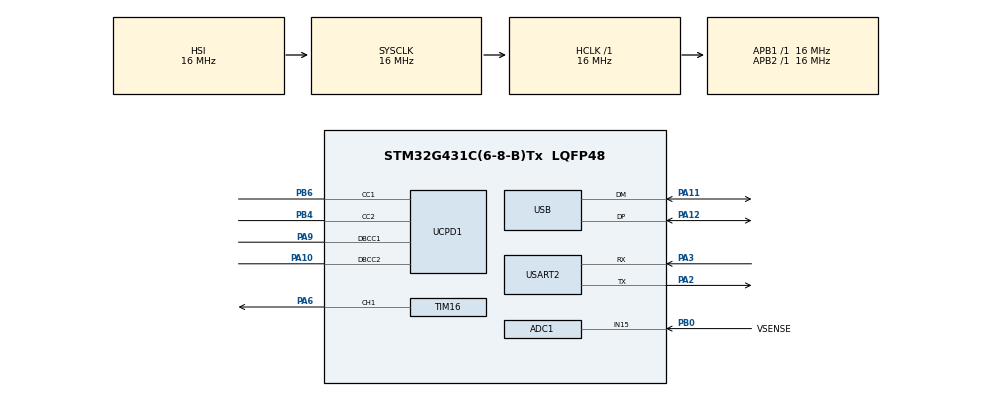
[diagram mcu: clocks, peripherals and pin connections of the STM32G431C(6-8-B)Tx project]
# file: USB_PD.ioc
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ADC1.Channel-0\#ChannelRegularConversion=ADC_CHANNEL_15
ADC1.ClockPrescaler=ADC_CLOCK_SYNC_PCLK_DIV4
ADC1.ContinuousConvMode=ENABLE
ADC1.NbrOfConversionFlag=1
ADC1.OffsetNumber-0\#ChannelRegularConversion=ADC_OFFSET_NONE
ADC1.Overrun=ADC_OVR_DATA_OVERWRITTEN
ADC1.Rank-0\#ChannelRegularConversion=1
ADC1.SamplingTime-0\#ChannelRegularConversion=ADC_SAMPLETIME_247CYCLES_5
ADC1.master=1
Dma.Request0=UCPD1_RX
Dma.Request1=UCPD1_TX
Dma.UCPD1_RX.0.Direction=DMA_PERIPH_TO_MEMORY
Dma.UCPD1_RX.0.EventEnable=DISABLE
Dma.UCPD1_RX.0.Instance=DMA1_Channel1
Dma.UCPD1_RX.0.MemDataAlignment=DMA_MDATAALIGN_BYTE
Dma.UCPD1_RX.0.MemInc=DMA_MINC_ENABLE
Dma.UCPD1_RX.0.Mode=DMA_NORMAL
Dma.UCPD1_RX.0.PeriphDataAlignment=DMA_PDATAALIGN_BYTE
Dma.UCPD1_RX.0.PeriphInc=DMA_PINC_DISABLE
Dma.UCPD1_RX.0.Polarity=HAL_DMAMUX_REQ_GEN_RISING
Dma.UCPD1_RX.0.Priority=DMA_PRIORITY_LOW
Dma.UCPD1_RX.0.RequestNumber=1
Dma.UCPD1_RX.0.SignalID=NONE
Dma.UCPD1_RX.0.SyncEnable=DISABLE
Dma.UCPD1_RX.0.SyncPolarity=HAL_DMAMUX_SYNC_NO_EVENT
Dma.UCPD1_RX.0.SyncRequestNumber=1
Dma.UCPD1_RX.0.SyncSignalID=NONE
Dma.UCPD1_TX.1.Direction=DMA_MEMORY_TO_PERIPH
Dma.UCPD1_TX.1.EventEnable=DISABLE
Dma.UCPD1_TX.1.Instance=DMA1_Channel2
Dma.UCPD1_TX.1.MemDataAlignment=DMA_MDATAALIGN_BYTE
Dma.UCPD1_TX.1.MemInc=DMA_MINC_ENABLE
Dma.UCPD1_TX.1.Mode=DMA_NORMAL
Dma.UCPD1_TX.1.PeriphDataAlignment=DMA_PDATAALIGN_BYTE
Dma.UCPD1_TX.1.PeriphInc=DMA_PINC_DISABLE
Dma.UCPD1_TX.1.Polarity=HAL_DMAMUX_REQ_GEN_RISING
Dma.UCPD1_TX.1.Priority=DMA_PRIORITY_LOW
Dma.UCPD1_TX.1.RequestNumber=1
Dma.UCPD1_TX.1.SignalID=NONE
Dma.UCPD1_TX.1.SyncEnable=DISABLE
Dma.UCPD1_TX.1.SyncPolarity=HAL_DMAMUX_SYNC_NO_EVENT
Dma.UCPD1_TX.1.SyncRequestNumber=1
Dma.UCPD1_TX.1.SyncSignalID=NONE
FREERTOS.INCLUDE_eTaskGetState=1
FREERTOS.Tasks01=defaultTask,24,128,StartDefaultTask,Default,NULL,Dynamic,NULL,NULL
FREERTOS.configTOTAL_HEAP_SIZE=7000
Mcu.Family=STM32G4
Mcu.Name=STM32G431C(6-8-B)Tx
Mcu.Package=LQFP48
Mcu.UserConstants=VDDA_APPLI,3300
NVIC.DMA1_Channel1_IRQn=true\:5\:0\:false\:false\:true\:true\:false\:true
NVIC.DMA1_Channel2_IRQn=true\:5\:0\:false\:false\:true\:true\:false\:true
NVIC.PriorityGroup=NVIC_PRIORITYGROUP_4
NVIC.UCPD1_IRQn=true\:5\:0\:false\:false\:true\:true\:true\:false
NVIC.USB_LP_IRQn=true\:5\:0\:false\:false\:true\:true\:false\:true
PA10.Mode=EnableDeadBattery
PA10.Signal=UCPD1_DBCC2
PA11.Mode=Device
PA11.Signal=USB_DM
PA12.Mode=Device
PA12.Signal=USB_DP
PA2.Mode=Asynchronous
PA2.Signal=USART2_TX
PA3.Mode=Asynchronous
PA3.Signal=USART2_RX
PA6.Signal=S_TIM16_CH1
PA9.Mode=EnableDeadBattery
PA9.Signal=UCPD1_DBCC1
PB0.GPIO_Label=VSENSE
PB0.Mode=IN15-Single-Ended
PB0.Signal=ADC1_IN15
PB4.Mode=Sink_AllSignals
PB4.Signal=UCPD1_CC2
PB6.Mode=Sink_AllSignals
PB6.Signal=UCPD1_CC1
ProjectManager.HeapSize=0x200
ProjectManager.StackSize=0x400
ProjectManager.TargetToolchain=EWARM V8.32
RCC.AHBFreq_Value=16000000
RCC.APB1Freq_Value=16000000
RCC.APB1TimFreq_Value=16000000
RCC.APB2Freq_Value=16000000
RCC.APB2TimFreq_Value=16000000
RCC.CortexFreq_Value=16000000
RCC.EXTERNAL_CLOCK_VALUE=12288000
RCC.HCLKFreq_Value=16000000
RCC.HSE_VALUE=8000000
RCC.HSI48_VALUE=48000000
RCC.HSI_VALUE=16000000
RCC.LSE_VALUE=32768
RCC.PLLN=12
RCC.PLLQ=RCC_PLLQ_DIV4
RCC.SYSCLKFreq_VALUE=16000000
RCC.USBFreq_Value=48000000
RCC.VCOOutputFreq_Value=192000000
SH.S_TIM16_CH1.0=TIM16_CH1,PWM Generation1 CH1
TIM16.Channel=TIM_CHANNEL_1
TIM16.PeriodNoDither=1000
TIM16.Prescaler=15
TIM16.PulseNoDither_1=600
USART2.VirtualMode-Asynchronous=VM_ASYNC
USB.battery_charging_enable=DISABLE
USB_DEVICE.CLASS_NAME_FS=CDC
USB_DEVICE.USBD_LPM_ENABLED=0
USB_DEVICE.USBD_SELF_POWERED=1
USB_DEVICE.VirtualMode=Cdc
USB_DEVICE.VirtualModeFS=Cdc_FS
VP_FREERTOS_VS_CMSIS_V2.Mode=CMSIS_V2
VP_SYS_VS_DBSignals.Mode=DisableDeadBatterySignals
VP_TIM16_VS_ClockSourceINT.Mode=Enable_Timer
VP_USBPD_VS_PD3TYPEC.Mode=PD3_TypeC
VP_USBPD_VS_USBPD1.Mode=USBPD_P0
VP_USBPD_VS_usbpd_tim1.Mode=TIM1
VP_USB_DEVICE_VS_USB_DEVICE_CDC_FS.Mode=CDC_FS
board=custom

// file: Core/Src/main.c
/* USER CODE BEGIN Header */
/**
  ******************************************************************************
  * @file           : main.c
  * @brief          : Main program body
  ******************************************************************************
  * @attention
  *
  * Copyright (c) 2022 STMicroelectronics.
  * All rights reserved.
  *
  * This software is licensed under terms that can be found in the LICENSE file
  * in the root directory of this software component.
  * If no LICENSE file comes with this software, it is provided AS-IS.
  *
  ******************************************************************************
  */
/* USER CODE END Header */
#include "main.h"
#include "cmsis_os.h"
#include "usbpd.h"
#include "usb_device.h"

/* USER CODE BEGIN Includes */
#include "usbd_cdc_if.h"
/* USER CODE END Includes */

ADC_HandleTypeDef hadc1;

TIM_HandleTypeDef htim16;

UART_HandleTypeDef huart2;

/* Definitions for defaultTask */
osThreadId_t defaultTaskHandle;
const osThreadAttr_t defaultTask_attributes = {
  .name = "defaultTask",
  .priority = (osPriority_t) osPriorityNormal,
  .stack_size = 128 * 4
};
/* USER CODE BEGIN PV */
uint8_t rX2Data[1];
/* USER CODE END PV */

void SystemClock_Config(void);
static void MX_GPIO_Init(void);
static void MX_ADC1_Init(void);
static void MX_DMA_Init(void);
static void MX_UCPD1_Init(void);
static void MX_USART2_UART_Init(void);
static void MX_TIM16_Init(void);
void StartDefaultTask(void *argument);

int main(void)
{

  /* MCU Configuration--------------------------------------------------------*/

  /* Reset of all peripherals, Initializes the Flash interface and the Systick. */
  HAL_Init();

  /* Configure the system clock */
  SystemClock_Config();

  /* Initialize all configured peripherals */
  MX_GPIO_Init();
  MX_ADC1_Init();
  MX_DMA_Init();
  MX_UCPD1_Init();
  MX_USB_Device_Init();
  MX_USART2_UART_Init();
  MX_TIM16_Init();
  /* USER CODE BEGIN 2 */
    HAL_ADCEx_Calibration_Start(&hadc1, ADC_SINGLE_ENDED);
    HAL_ADC_Start(&hadc1);
  /* USER CODE END 2 */

  /* Init scheduler */
  osKernelInitialize();
  /* USBPD initialisation ---------------------------------*/
  MX_USBPD_Init();

  /* Create the thread(s) */
  /* creation of defaultTask */
  defaultTaskHandle = osThreadNew(StartDefaultTask, NULL, &defaultTask_attributes);

  /* Start scheduler */
  osKernelStart();

  /* We should never get here as control is now taken by the scheduler */
  /* Infinite loop */
  while (1)
  {

  }
}

void SystemClock_Config(void)
{
  RCC_OscInitTypeDef RCC_OscInitStruct = {0};
  RCC_ClkInitTypeDef RCC_ClkInitStruct = {0};

  /** Configure the main internal regulator output voltage
  */
  HAL_PWREx_ControlVoltageScaling(PWR_REGULATOR_VOLTAGE_SCALE1);
  /** Initializes the RCC Oscillators according to the specified parameters
  * in the RCC_OscInitTypeDef structure.
  */
  RCC_OscInitStruct.OscillatorType = RCC_OSCILLATORTYPE_HSI;
  RCC_OscInitStruct.HSIState = RCC_HSI_ON;
  RCC_OscInitStruct.HSICalibrationValue = RCC_HSICALIBRATION_DEFAULT;
  RCC_OscInitStruct.PLL.PLLState = RCC_PLL_ON;
  RCC_OscInitStruct.PLL.PLLSource = RCC_PLLSOURCE_HSI;
  RCC_OscInitStruct.PLL.PLLM = RCC_PLLM_DIV1;
  RCC_OscInitStruct.PLL.PLLN = 12;
  RCC_OscInitStruct.PLL.PLLP = RCC_PLLP_DIV2;
  RCC_OscInitStruct.PLL.PLLQ = RCC_PLLQ_DIV4;
  RCC_OscInitStruct.PLL.PLLR = RCC_PLLR_DIV2;
  if (HAL_RCC_OscConfig(&RCC_OscInitStruct) != HAL_OK)
  {
    Error_Handler();
  }
  /** Initializes the CPU, AHB and APB buses clocks
  */
  RCC_ClkInitStruct.ClockType = RCC_CLOCKTYPE_HCLK|RCC_CLOCKTYPE_SYSCLK
                              |RCC_CLOCKTYPE_PCLK1|RCC_CLOCKTYPE_PCLK2;
  RCC_ClkInitStruct.SYSCLKSource = RCC_SYSCLKSOURCE_HSI;
  RCC_ClkInitStruct.AHBCLKDivider = RCC_SYSCLK_DIV1;
  RCC_ClkInitStruct.APB1CLKDivider = RCC_HCLK_DIV1;
  RCC_ClkInitStruct.APB2CLKDivider = RCC_HCLK_DIV1;

  if (HAL_RCC_ClockConfig(&RCC_ClkInitStruct, FLASH_LATENCY_0) != HAL_OK)
  {
    Error_Handler();
  }
}

static void MX_ADC1_Init(void)
{

  ADC_MultiModeTypeDef multimode = {0};
  ADC_ChannelConfTypeDef sConfig = {0};

  /** Common config
  */
  hadc1.Instance = ADC1;
  hadc1.Init.ClockPrescaler = ADC_CLOCK_SYNC_PCLK_DIV4;
  hadc1.Init.Resolution = ADC_RESOLUTION_12B;
  hadc1.Init.DataAlign = ADC_DATAALIGN_RIGHT;
  hadc1.Init.GainCompensation = 0;
  hadc1.Init.ScanConvMode = ADC_SCAN_DISABLE;
  hadc1.Init.EOCSelection = ADC_EOC_SINGLE_CONV;
  hadc1.Init.LowPowerAutoWait = DISABLE;
  hadc1.Init.ContinuousConvMode = ENABLE;
  hadc1.Init.NbrOfConversion = 1;
  hadc1.Init.DiscontinuousConvMode = DISABLE;
  hadc1.Init.ExternalTrigConv = ADC_SOFTWARE_START;
  hadc1.Init.ExternalTrigConvEdge = ADC_EXTERNALTRIGCONVEDGE_NONE;
  hadc1.Init.DMAContinuousRequests = DISABLE;
  hadc1.Init.Overrun = ADC_OVR_DATA_OVERWRITTEN;
  hadc1.Init.OversamplingMode = DISABLE;
  if (HAL_ADC_Init(&hadc1) != HAL_OK)
  {
    Error_Handler();
  }
  /** Configure the ADC multi-mode
  */
  multimode.Mode = ADC_MODE_INDEPENDENT;
  if (HAL_ADCEx_MultiModeConfigChannel(&hadc1, &multimode) != HAL_OK)
  {
    Error_Handler();
  }
  /** Configure Regular Channel
  */
  sConfig.Channel = ADC_CHANNEL_15;
  sConfig.Rank = ADC_REGULAR_RANK_1;
  sConfig.SamplingTime = ADC_SAMPLETIME_247CYCLES_5;
  sConfig.SingleDiff = ADC_SINGLE_ENDED;
  sConfig.OffsetNumber = ADC_OFFSET_NONE;
  sConfig.Offset = 0;
  if (HAL_ADC_ConfigChannel(&hadc1, &sConfig) != HAL_OK)
  {
    Error_Handler();
  }

}

static void MX_TIM16_Init(void)
{

  TIM_OC_InitTypeDef sConfigOC = {0};
  TIM_BreakDeadTimeConfigTypeDef sBreakDeadTimeConfig = {0};

  htim16.Instance = TIM16;
  htim16.Init.Prescaler = 15;
  htim16.Init.CounterMode = TIM_COUNTERMODE_UP;
  htim16.Init.Period = 1000;
  htim16.Init.ClockDivision = TIM_CLOCKDIVISION_DIV1;
  htim16.Init.RepetitionCounter = 0;
  htim16.Init.AutoReloadPreload = TIM_AUTORELOAD_PRELOAD_DISABLE;
  if (HAL_TIM_Base_Init(&htim16) != HAL_OK)
  {
    Error_Handler();
  }
  if (HAL_TIM_PWM_Init(&htim16) != HAL_OK)
  {
    Error_Handler();
  }
  sConfigOC.OCMode = TIM_OCMODE_PWM1;
  sConfigOC.Pulse = 600;
  sConfigOC.OCPolarity = TIM_OCPOLARITY_HIGH;
  sConfigOC.OCNPolarity = TIM_OCNPOLARITY_HIGH;
  sConfigOC.OCFastMode = TIM_OCFAST_DISABLE;
  sConfigOC.OCIdleState = TIM_OCIDLESTATE_RESET;
  sConfigOC.OCNIdleState = TIM_OCNIDLESTATE_RESET;
  if (HAL_TIM_PWM_ConfigChannel(&htim16, &sConfigOC, TIM_CHANNEL_1) != HAL_OK)
  {
    Error_Handler();
  }
  sBreakDeadTimeConfig.OffStateRunMode = TIM_OSSR_DISABLE;
  sBreakDeadTimeConfig.OffStateIDLEMode = TIM_OSSI_DISABLE;
  sBreakDeadTimeConfig.LockLevel = TIM_LOCKLEVEL_OFF;
  sBreakDeadTimeConfig.DeadTime = 0;
  sBreakDeadTimeConfig.BreakState = TIM_BREAK_DISABLE;
  sBreakDeadTimeConfig.BreakPolarity = TIM_BREAKPOLARITY_HIGH;
  sBreakDeadTimeConfig.BreakFilter = 0;
  sBreakDeadTimeConfig.AutomaticOutput = TIM_AUTOMATICOUTPUT_DISABLE;
  if (HAL_TIMEx_ConfigBreakDeadTime(&htim16, &sBreakDeadTimeConfig) != HAL_OK)
  {
    Error_Handler();
  }
  HAL_TIM_MspPostInit(&htim16);

}

static void MX_UCPD1_Init(void)
{

  LL_GPIO_InitTypeDef GPIO_InitStruct = {0};

  /* Peripheral clock enable */
  LL_APB1_GRP2_EnableClock(LL_APB1_GRP2_PERIPH_UCPD1);

  LL_AHB2_GRP1_EnableClock(LL_AHB2_GRP1_PERIPH_GPIOB);
  /**UCPD1 GPIO Configuration
  PB4   ------> UCPD1_CC2
  PB6   ------> UCPD1_CC1
  */
  GPIO_InitStruct.Pin = LL_GPIO_PIN_4;
  GPIO_InitStruct.Mode = LL_GPIO_MODE_ANALOG;
  GPIO_InitStruct.Pull = LL_GPIO_PULL_NO;
  LL_GPIO_Init(GPIOB, &GPIO_InitStruct);

  GPIO_InitStruct.Pin = LL_GPIO_PIN_6;
  GPIO_InitStruct.Mode = LL_GPIO_MODE_ANALOG;
  GPIO_InitStruct.Pull = LL_GPIO_PULL_NO;
  LL_GPIO_Init(GPIOB, &GPIO_InitStruct);

  /* UCPD1 DMA Init */

  /* UCPD1_RX Init */
  LL_DMA_SetPeriphRequest(DMA1, LL_DMA_CHANNEL_1, LL_DMAMUX_REQ_UCPD1_RX);

  LL_DMA_SetDataTransferDirection(DMA1, LL_DMA_CHANNEL_1, LL_DMA_DIRECTION_PERIPH_TO_MEMORY);

  LL_DMA_SetChannelPriorityLevel(DMA1, LL_DMA_CHANNEL_1, LL_DMA_PRIORITY_LOW);

  LL_DMA_SetMode(DMA1, LL_DMA_CHANNEL_1, LL_DMA_MODE_NORMAL);

  LL_DMA_SetPeriphIncMode(DMA1, LL_DMA_CHANNEL_1, LL_DMA_PERIPH_NOINCREMENT);

  LL_DMA_SetMemoryIncMode(DMA1, LL_DMA_CHANNEL_1, LL_DMA_MEMORY_INCREMENT);

  LL_DMA_SetPeriphSize(DMA1, LL_DMA_CHANNEL_1, LL_DMA_PDATAALIGN_BYTE);

  LL_DMA_SetMemorySize(DMA1, LL_DMA_CHANNEL_1, LL_DMA_MDATAALIGN_BYTE);

  /* UCPD1_TX Init */
  LL_DMA_SetPeriphRequest(DMA1, LL_DMA_CHANNEL_2, LL_DMAMUX_REQ_UCPD1_TX);

  LL_DMA_SetDataTransferDirection(DMA1, LL_DMA_CHANNEL_2, LL_DMA_DIRECTION_MEMORY_TO_PERIPH);

  LL_DMA_SetChannelPriorityLevel(DMA1, LL_DMA_CHANNEL_2, LL_DMA_PRIORITY_LOW);

  LL_DMA_SetMode(DMA1, LL_DMA_CHANNEL_2, LL_DMA_MODE_NORMAL);

  LL_DMA_SetPeriphIncMode(DMA1, LL_DMA_CHANNEL_2, LL_DMA_PERIPH_NOINCREMENT);

  LL_DMA_SetMemoryIncMode(DMA1, LL_DMA_CHANNEL_2, LL_DMA_MEMORY_INCREMENT);

  LL_DMA_SetPeriphSize(DMA1, LL_DMA_CHANNEL_2, LL_DMA_PDATAALIGN_BYTE);

  LL_DMA_SetMemorySize(DMA1, LL_DMA_CHANNEL_2, LL_DMA_MDATAALIGN_BYTE);

  /* UCPD1 interrupt Init */
  NVIC_SetPriority(UCPD1_IRQn, NVIC_EncodePriority(NVIC_GetPriorityGrouping(),5, 0));
  NVIC_EnableIRQ(UCPD1_IRQn);

}

static void MX_USART2_UART_Init(void)
{

  huart2.Instance = USART2;
  huart2.Init.BaudRate = 115200;
  huart2.Init.WordLength = UART_WORDLENGTH_8B;
  huart2.Init.StopBits = UART_STOPBITS_1;
  huart2.Init.Parity = UART_PARITY_NONE;
  huart2.Init.Mode = UART_MODE_TX_RX;
  huart2.Init.HwFlowCtl = UART_HWCONTROL_NONE;
  huart2.Init.OverSampling = UART_OVERSAMPLING_16;
  huart2.Init.OneBitSampling = UART_ONE_BIT_SAMPLE_DISABLE;
  huart2.Init.ClockPrescaler = UART_PRESCALER_DIV1;
  huart2.AdvancedInit.AdvFeatureInit = UART_ADVFEATURE_NO_INIT;
  if (HAL_UART_Init(&huart2) != HAL_OK)
  {
    Error_Handler();
  }
  if (HAL_UARTEx_SetTxFifoThreshold(&huart2, UART_TXFIFO_THRESHOLD_1_8) != HAL_OK)
  {
    Error_Handler();
  }
  if (HAL_UARTEx_SetRxFifoThreshold(&huart2, UART_RXFIFO_THRESHOLD_1_8) != HAL_OK)
  {
    Error_Handler();
  }
  if (HAL_UARTEx_DisableFifoMode(&huart2) != HAL_OK)
  {
    Error_Handler();
  }

}

static void MX_DMA_Init(void)
{

  /* DMA controller clock enable */
  __HAL_RCC_DMAMUX1_CLK_ENABLE();
  __HAL_RCC_DMA1_CLK_ENABLE();

  /* DMA interrupt init */
  /* DMA1_Channel1_IRQn interrupt configuration */
  NVIC_SetPriority(DMA1_Channel1_IRQn, NVIC_EncodePriority(NVIC_GetPriorityGrouping(),5, 0));
  NVIC_EnableIRQ(DMA1_Channel1_IRQn);
  /* DMA1_Channel2_IRQn interrupt configuration */
  NVIC_SetPriority(DMA1_Channel2_IRQn, NVIC_EncodePriority(NVIC_GetPriorityGrouping(),5, 0));
  NVIC_EnableIRQ(DMA1_Channel2_IRQn);

}

static void MX_GPIO_Init(void)
{
  GPIO_InitTypeDef GPIO_InitStruct = {0};

  /* GPIO Ports Clock Enable */
  __HAL_RCC_GPIOC_CLK_ENABLE();
  __HAL_RCC_GPIOF_CLK_ENABLE();
  __HAL_RCC_GPIOG_CLK_ENABLE();
  __HAL_RCC_GPIOA_CLK_ENABLE();
  __HAL_RCC_GPIOB_CLK_ENABLE();

  /*Configure GPIO pins : PC13 PC14 PC15 */
  GPIO_InitStruct.Pin = GPIO_PIN_13|GPIO_PIN_14|GPIO_PIN_15;
  GPIO_InitStruct.Mode = GPIO_MODE_ANALOG;
  GPIO_InitStruct.Pull = GPIO_NOPULL;
  HAL_GPIO_Init(GPIOC, &GPIO_InitStruct);

  /*Configure GPIO pins : PF0 PF1 */
  GPIO_InitStruct.Pin = GPIO_PIN_0|GPIO_PIN_1;
  GPIO_InitStruct.Mode = GPIO_MODE_ANALOG;
  GPIO_InitStruct.Pull = GPIO_NOPULL;
  HAL_GPIO_Init(GPIOF, &GPIO_InitStruct);

  /*Configure GPIO pin : PG10 */
  GPIO_InitStruct.Pin = GPIO_PIN_10;
  GPIO_InitStruct.Mode = GPIO_MODE_ANALOG;
  GPIO_InitStruct.Pull = GPIO_NOPULL;
  HAL_GPIO_Init(GPIOG, &GPIO_InitStruct);

  /*Configure GPIO pins : PA0 PA1 PA4 PA5
                           PA7 PA8 PA13 PA14
                           PA15 */
  GPIO_InitStruct.Pin = GPIO_PIN_0|GPIO_PIN_1|GPIO_PIN_4|GPIO_PIN_5
                          |GPIO_PIN_7|GPIO_PIN_8|GPIO_PIN_13|GPIO_PIN_14
                          |GPIO_PIN_15;
  GPIO_InitStruct.Mode = GPIO_MODE_ANALOG;
  GPIO_InitStruct.Pull = GPIO_NOPULL;
  HAL_GPIO_Init(GPIOA, &GPIO_InitStruct);

  /*Configure GPIO pins : PB1 PB2 PB10 PB11
                           PB12 PB13 PB14 PB15
                           PB3 PB5 PB7 PB8
                           PB9 */
  GPIO_InitStruct.Pin = GPIO_PIN_1|GPIO_PIN_2|GPIO_PIN_10|GPIO_PIN_11
                          |GPIO_PIN_12|GPIO_PIN_13|GPIO_PIN_14|GPIO_PIN_15
                          |GPIO_PIN_3|GPIO_PIN_5|GPIO_PIN_7|GPIO_PIN_8
                          |GPIO_PIN_9;
  GPIO_InitStruct.Mode = GPIO_MODE_ANALOG;
  GPIO_InitStruct.Pull = GPIO_NOPULL;
  HAL_GPIO_Init(GPIOB, &GPIO_InitStruct);

}

/* USER CODE BEGIN 4 */
/**
  * @brief  Rx Transfer completed callback.
  * @param  huart UART handle.
  * @retval None
  */
void HAL_UART_RxCpltCallback(UART_HandleTypeDef *huart)
{

}
/* USER CODE END 4 */

void StartDefaultTask(void *argument)
{
  /* USER CODE BEGIN 5 */
  //uint8_t data[]="Hello World from USB CDC\n";

  //HAL_Delay(1000);
  HAL_TIM_PWM_Start(&htim16,TIM_CHANNEL_1);
  /* Infinite loop */
  for(;;)
  {

    HAL_UART_Receive(&huart2, rX2Data,1, 1000);
    CDC_Transmit_FS(rX2Data, sizeof(rX2Data));
    //CDC_Transmit_FS(data, sizeof(data));
    osDelay(1);
  }
  /* USER CODE END 5 */
}

void Error_Handler(void)
{
  __disable_irq();
  while (1)
  {
  }
}
